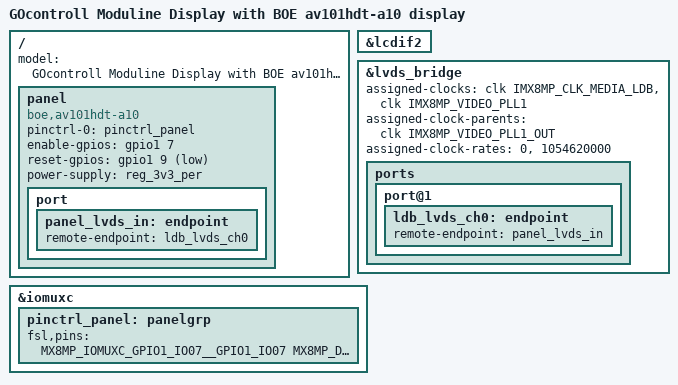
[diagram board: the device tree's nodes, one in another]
// SPDX-License-Identifier: (GPL-2.0 OR MIT)
/*
 * Copyright 2025 GOcontroll B.V.
 * Author: Maud Spierings <maudspierings@gocontroll.com>
 */

/dts-v1/;

#include "imx8mp-tx8p-ml81-moduline-display-106.dtsi"

/ {
	model = "GOcontroll Moduline Display with BOE av101hdt-a10 display";

	panel {
		compatible = "boe,av101hdt-a10";
		pinctrl-names = "default";
		pinctrl-0 = <&pinctrl_panel>;
		enable-gpios = <&gpio1 7 GPIO_ACTIVE_HIGH>;
		reset-gpios = <&gpio1 9 GPIO_ACTIVE_LOW>;
		power-supply = <&reg_3v3_per>;

		port {
			panel_lvds_in: endpoint {
				remote-endpoint = <&ldb_lvds_ch0>;
			};
		};
	};
};

&lcdif2 {
	status = "okay";
};

&lvds_bridge {
	assigned-clocks = <&clk IMX8MP_CLK_MEDIA_LDB>,
	<&clk IMX8MP_VIDEO_PLL1>;
	assigned-clock-parents = <&clk IMX8MP_VIDEO_PLL1_OUT>;
	/* IMX8MP_VIDEO_PLL1 = IMX8MP_CLK_MEDIA_DISP2_PIX * 2 * 7 */
	assigned-clock-rates = <0>, <1054620000>;
	status = "okay";

	ports {
		port@1 {
			ldb_lvds_ch0: endpoint {
				remote-endpoint = <&panel_lvds_in>;
			};
		};
	};
};

&iomuxc {
	pinctrl_panel: panelgrp {
		fsl,pins = <
			MX8MP_IOMUXC_GPIO1_IO07__GPIO1_IO07 /* COM pin 157 */
			MX8MP_DSE_X1
			MX8MP_IOMUXC_GPIO1_IO09__GPIO1_IO09 /* COM pin 159 */
			MX8MP_DSE_X1
		>;
	};
};
